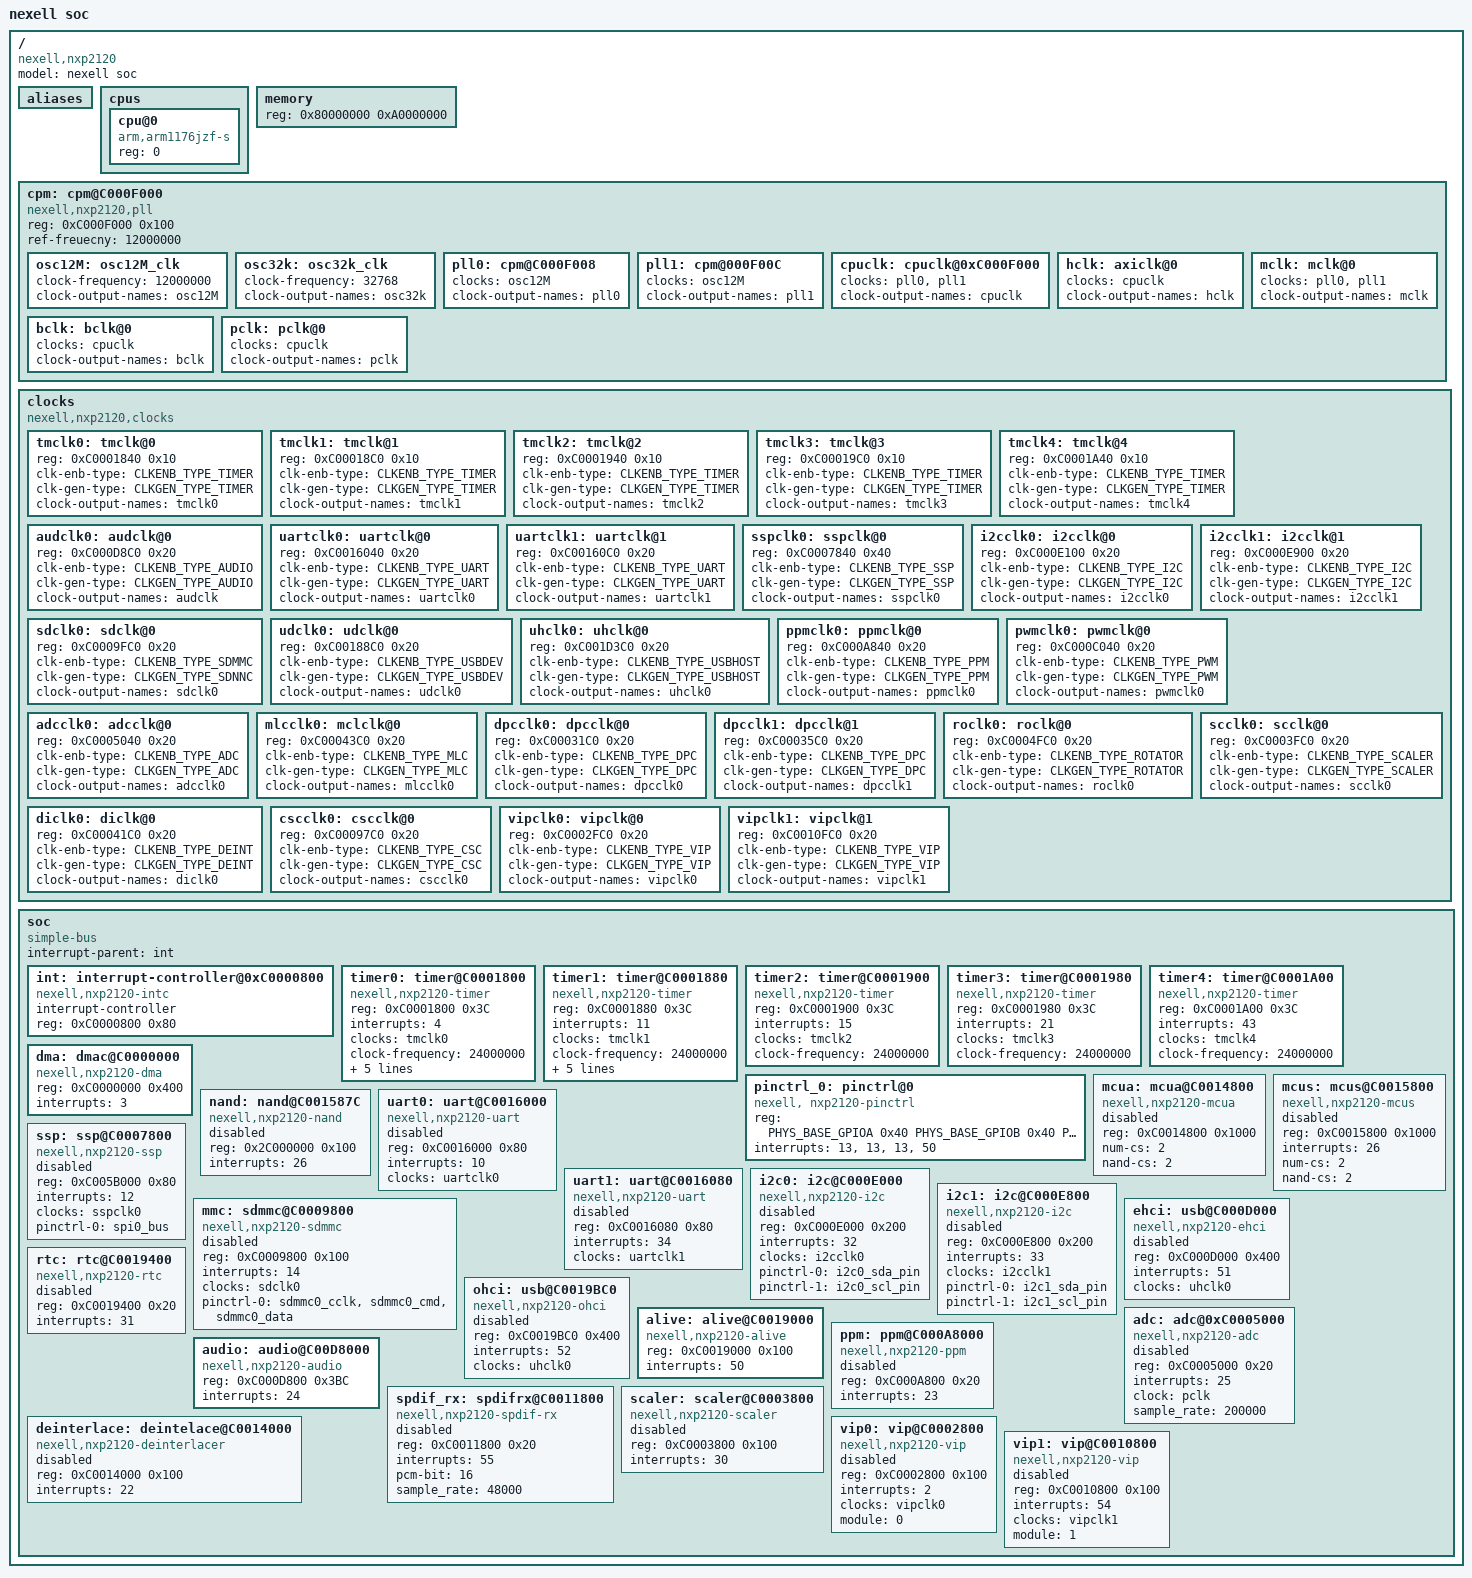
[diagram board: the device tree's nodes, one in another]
/*
 * Copyright (C) 2019 I4VINE
 * Author: Juyoung Ryu <jyryu@i4vine.com>	
 *
 * Copyright (C) 2016 STcube Inc.,
 * All right reserved Seungwoo Kim <ksw@stcube.com>
 *
 * This file is dual-licensed: you can use it either under the terms
 * of the GPL or the X11 license, at your option. Note that this dual
 * licensing only applies to this file, and not this project as a
 * whole.
 *
 *  a) This file is free software; you can redistribute it and/or
 *     modify it under the terms of the GNU General Public License as
 *     published by the Free Software Foundation; either version 2 of the
 *     License, or (at your option) any later version.
 *
 *     This file is distributed in the hope that it will be useful,
 *     but WITHOUT ANY WARRANTY; without even the implied warranty of
 *     MERCHANTABILITY or FITNESS FOR A PARTICULAR PURPOSE.  See the
 *     GNU General Public License for more details.
 *
 * Or, alternatively,
 *
 *  b) Permission is hereby granted, free of charge, to any person
 *     obtaining a copy of this software and associated documentation
 *     files (the "Software"), to deal in the Software without
 *     restriction, including without limitation the rights to use,
 *     copy, modify, merge, publish, distribute, sublicense, and/or
 *     sell copies of the Software, and to permit persons to whom the
 *     Software is furnished to do so, subject to the following
 *     conditions:
 *
 *     The above copyright notice and this permission notice shall be
 *     included in all copies or substantial portions of the Software.
 *
 *     THE SOFTWARE IS PROVIDED "AS IS", WITHOUT WARRANTY OF ANY KIND,
 *     EXPRESS OR IMPLIED, INCLUDING BUT NOT LIMITED TO THE WARRANTIES
 *     OF MERCHANTABILITY, FITNESS FOR A PARTICULAR PURPOSE AND
 *     NONINFRINGEMENT. IN NO EVENT SHALL THE AUTHORS OR COPYRIGHT
 *     HOLDERS BE LIABLE FOR ANY CLAIM, DAMAGES OR OTHER LIABILITY,
 *     WHETHER IN AN ACTION OF CONTRACT, TORT OR OTHERWISE, ARISING
 *     FROM, OUT OF OR IN CONNECTION WITH THE SOFTWARE OR THE USE OR
 *     OTHER DEALINGS IN THE SOFTWARE.
 */
 
/*#include "skeleton.dtsi"
#include <dt-bindings/interrupt-controller/irq.h>*/
#include <dt-bindings/soc/nxp2120-base.h>
#include <dt-bindings/clk/nxp2120-clk.h>
/dts-v1/;


/ {
	model = "nexell soc";
	compatible = "nexell,nxp2120";
	#address-cells = <0x1>;
	#size-cells = <0x1>;
	
	aliases {
		/*pinctrl0 = &pinctrl_0;*/
	};
	cpus {
		#address-cells = <1>;
		#size-cells = <0>;
	/*	enable-method = "nexell,nxp2120-smp";*/
		

		cpu@0 {
			compatible = "arm,arm1176jzf-s","arm,arm1176","arm,armv6";
			device_type = "cpu";
			reg = <0>;
		};
	};
	
	memory {
		reg = <0x80000000 0xA0000000>;
	};

	cpm:cpm@C000F000 {
		compatible = "nexell,nxp2120,pll";
		reg = <0xC000F000 0x100>;
		ref-freuecny = <12000000>;
		status = "okay";

		osc12M: osc12M_clk {
			#clock-cells = <0>;
			clock-frequency = <12000000>;
			clock-output-names = "osc12M";
		};

		osc32k: osc32k_clk {
			#clock-cells = <0>;
			clock-frequency = <32768>;
			clock-output-names = "osc32k";
		};

		pll0: cpm@C000F008 {
			#clock-cells = <0>;
			clocks = <&osc12M>;
			clock-output-names = "pll0";
		};

		pll1: cpm@000F00C {
			#clock-cells = <0>;
			clocks = <&osc12M>;
			clock-output-names = "pll1";
		};

		cpuclk: cpuclk@0xC000F000 {
			#clock-cells = <0>;
			clocks = <&pll0>,<&pll1>;
			clock-output-names = "cpuclk";
		};

		hclk: axiclk@0 {
			#clock-cells = <0>;
			clocks = <&cpuclk>;
			clock-output-names = "hclk";
		};

		mclk: mclk@0 {
			#clock-cells = <0>;
			clocks = <&pll0>,<&pll1>;
			clock-output-names = "mclk";
		};

		bclk: bclk@0 {
			#clock-cells = <0>;
			clocks = <&cpuclk>;
			clock-output-names = "bclk";
		};

		pclk: pclk@0 {
			#clock-cells = <0>;
			clocks = <&cpuclk>;
			clock-output-names = "pclk";
		};

	};

	clocks {
		#address-cells = <1>;
		#size-cells = <1>;
		compatible = "nexell,nxp2120,clocks";
		ranges;

		tmclk0: tmclk@0 {
			reg = <0xC0001840 0x10>;
			clk-enb-type = <CLKENB_TYPE_TIMER>;
			clk-gen-type = <CLKGEN_TYPE_TIMER>;
			clock-output-names = "tmclk0";
		};
		tmclk1: tmclk@1 {
			reg = <0xC00018C0 0x10>;		
			clk-enb-type = <CLKENB_TYPE_TIMER>;
			clk-gen-type = <CLKGEN_TYPE_TIMER>;
			clock-output-names = "tmclk1";
		};
		tmclk2: tmclk@2 {
			reg = <0xC0001940 0x10>;
			clk-enb-type = <CLKENB_TYPE_TIMER>;
			clk-gen-type = <CLKGEN_TYPE_TIMER>;
			clock-output-names = "tmclk2";
		};
		tmclk3: tmclk@3 {
			reg = <0xC00019C0 0x10>;
			clk-enb-type = <CLKENB_TYPE_TIMER>;
			clk-gen-type = <CLKGEN_TYPE_TIMER>;
			clock-output-names = "tmclk3";
		};
		tmclk4: tmclk@4 {
			reg = <0xC0001A40 0x10>;
			clk-enb-type = <CLKENB_TYPE_TIMER>;
			clk-gen-type = <CLKGEN_TYPE_TIMER>;
			clock-output-names = "tmclk4";
		};
		audclk0: audclk@0 {
			reg = <0xC000D8C0 0x20>;
			clk-enb-type = <CLKENB_TYPE_AUDIO>;
			clk-gen-type = <CLKGEN_TYPE_AUDIO>;
			clock-output-names = "audclk";
		};
		uartclk0: uartclk@0 {
			reg = <0xC0016040 0x20>;
			clk-enb-type = <CLKENB_TYPE_UART>;
			clk-gen-type = <CLKGEN_TYPE_UART>;
			clock-output-names = "uartclk0";
		};
		uartclk1: uartclk@1 {
			reg = <0xC00160C0 0x20>;
			clk-enb-type = <CLKENB_TYPE_UART>;
			clk-gen-type = <CLKGEN_TYPE_UART>;
			clock-output-names = "uartclk1";
		};
		sspclk0: sspclk@0 {
			reg = <0xC0007840 0x40>;
			clk-enb-type = <CLKENB_TYPE_SSP>;
			clk-gen-type = <CLKGEN_TYPE_SSP>;
			clock-output-names = "sspclk0";
		};
		i2cclk0: i2cclk@0 {
			reg = <0xC000E100 0x20>;
			clk-enb-type = <CLKENB_TYPE_I2C>;
			clk-gen-type = <CLKGEN_TYPE_I2C>;
			clock-output-names = "i2cclk0";
		};
		i2cclk1: i2cclk@1 {
			reg = <0xC000E900 0x20>;
			clk-enb-type = <CLKENB_TYPE_I2C>;
			clk-gen-type = <CLKGEN_TYPE_I2C>;
			clock-output-names = "i2cclk1";
		};
		sdclk0: sdclk@0 {
			reg = <0xC0009FC0 0x20>;
			clk-enb-type = <CLKENB_TYPE_SDMMC>;
			clk-gen-type = <CLKGEN_TYPE_SDNNC>;			
			clock-output-names = "sdclk0";
		};
		udclk0: udclk@0 {
			reg = <0xC00188C0 0x20>;
			clk-enb-type = <CLKENB_TYPE_USBDEV>;
			clk-gen-type = <CLKGEN_TYPE_USBDEV>;
			clock-output-names="udclk0";
		};
		uhclk0: uhclk@0 {
			reg = <0xC001D3C0 0x20>;
			clk-enb-type = <CLKENB_TYPE_USBHOST>;
			clk-gen-type = <CLKGEN_TYPE_USBHOST>;
			clock-output-names="uhclk0";
		};
		ppmclk0: ppmclk@0 {
			reg = <0xC000A840 0x20>;
			clk-enb-type = <CLKENB_TYPE_PPM>;
			clk-gen-type = <CLKGEN_TYPE_PPM>;
			clock-output-names="ppmclk0";
		};
		pwmclk0: pwmclk@0 {
			reg = <0xC000C040 0x20>;
			clk-enb-type = <CLKENB_TYPE_PWM>;
			clk-gen-type = <CLKGEN_TYPE_PWM>;
			clock-output-names="pwmclk0";
		};
		adcclk0: adcclk@0 {
			reg = <0xC0005040 0x20>;
			clk-enb-type = <CLKENB_TYPE_ADC>;
			clk-gen-type = <CLKGEN_TYPE_ADC>;
			clock-output-names="adcclk0";
		};
		mlcclk0: mclclk@0 {
			reg = <0xC00043C0 0x20>;
			clk-enb-type = <CLKENB_TYPE_MLC>;
			clk-gen-type = <CLKGEN_TYPE_MLC>;
			clock-output-names="mlcclk0";
		};
		dpcclk0: dpcclk@0 {
			reg = <0xC00031C0 0x20>;
			clk-enb-type = <CLKENB_TYPE_DPC>;
			clk-gen-type = <CLKGEN_TYPE_DPC>;
			clock-output-names="dpcclk0";
		};
		dpcclk1: dpcclk@1 {
			reg = <0xC00035C0 0x20>;
			clk-enb-type = <CLKENB_TYPE_DPC>;
			clk-gen-type = <CLKGEN_TYPE_DPC>;
			clock-output-names="dpcclk1";
		};
		roclk0: roclk@0 {
			reg = <0xC0004FC0 0x20>;
			clk-enb-type = <CLKENB_TYPE_ROTATOR>;
			clk-gen-type = <CLKGEN_TYPE_ROTATOR>;
			clock-output-names="roclk0";
		};
		scclk0: scclk@0 {
			reg = <0xC0003FC0 0x20>;
			clk-enb-type = <CLKENB_TYPE_SCALER>;
			clk-gen-type = <CLKGEN_TYPE_SCALER>;
			clock-output-names="scclk0";
		};
		diclk0: diclk@0 {
			reg = <0xC00041C0 0x20>;
			clk-enb-type = <CLKENB_TYPE_DEINT>;
			clk-gen-type = <CLKGEN_TYPE_DEINT>;
			clock-output-names="diclk0";
		};
		cscclk0: cscclk@0 {
			reg = <0xC00097C0 0x20>;
			clk-enb-type = <CLKENB_TYPE_CSC>;
			clk-gen-type = <CLKGEN_TYPE_CSC>;
			clock-output-names="cscclk0";
		};
		vipclk0: vipclk@0 {
			reg = <0xC0002FC0 0x20>;
			clk-enb-type = <CLKENB_TYPE_VIP>;
			clk-gen-type = <CLKGEN_TYPE_VIP>;
			clock-output-names="vipclk0";
		};
		vipclk1: vipclk@1 {
			reg = <0xC0010FC0 0x20>;
			clk-enb-type = <CLKENB_TYPE_VIP>;
			clk-gen-type = <CLKGEN_TYPE_VIP>;
			clock-output-names="vipclk1";
		};
	};
	
	soc {
		compatible = "simple-bus";
		#address-cells = <1>;
		#size-cells = <1>;
		interrupt-parent = <&int>;
		ranges;

		int: interrupt-controller@0xC0000800 {
			compatible = "nexell,nxp2120-intc";
			interrupt-controller;
			reg = <0xC0000800 0x80>;
			#interrupt-cells = <1>;
		};
		
		timer0: timer@C0001800  {
			compatible = "nexell,nxp2120-timer";
			reg = <0xC0001800 0x3C>;		
			interrupts = <4>;		
			clocks =  <&tmclk0>;
			clock-names = "tmclk0";
			clock-frequency = <24000000>;	
			ch = <0>;
			clksrc = <1>; //pll1
			clkdiv = <64>;
			clkfreq = <3000000>;
			period = <0xffffffff>;			
		};
	
		timer1: timer@C0001880  {
			compatible = "nexell,nxp2120-timer";
			reg = <0xC0001880 0x3C>;		
			interrupts = <11>;
			clocks =  <&tmclk1>;
			clock-names = "tmclk1";		
			clock-frequency = <24000000>;
			ch = <1>;
			clksrc = <1>; //pll1
			clkdiv = <192>;
			clkfreq = <1000000>;	
			period = <0xffffffff>;			
		};
		
		timer2: timer@C0001900  {
			compatible = "nexell,nxp2120-timer";
			reg = <0xC0001900 0x3C>;		
			interrupts = <15>;	
			clocks =  <&tmclk2>;
			clock-names = "tmclk2";				
			clock-frequency = <24000000>;
	
		};
		
		timer3: timer@C0001980  {
			compatible = "nexell,nxp2120-timer";
			reg = <0xC0001980 0x3C>;		
			interrupts = <21>;
			clocks =  <&tmclk3>;
			clock-names = "tmclk3";				
			clock-frequency = <24000000>;
		};
		
		timer4: timer@C0001A00  {
			compatible = "nexell,nxp2120-timer";
			reg = <0xC0001A00 0x3C>;		
			interrupts = <43>;	
			clocks =  <&tmclk4>;
			clock-names = "tmclk4";			
			clock-frequency = <24000000>;
		};


		dma: dmac@C0000000 {
			compatible = "nexell,nxp2120-dma";
			reg = <0xC0000000 0x400>;
			interrupts = <3>;
		};
		
		pinctrl_0: pinctrl@0 {
			compatible = "nexell, nxp2120-pinctrl";
			reg = <PHYS_BASE_GPIOA 0x40
				   PHYS_BASE_GPIOB 0x40
				   PHYS_BASE_GPIOC 0x40
				   PHYS_BASE_ALIVE 0xC0>;
			#address-cells = <1>;
			#size-cells = <1>;
			interrupts = <13>,
					 <13>,
					 <13>,   
					 <50>;
		};

		mcua:mcua@C0014800 {
			compatible = "nexell,nxp2120-mcua";
			#address-cells = <1>;
			#size-cells = <0>;
			reg = <0xC0014800 0x1000>;
			num-cs = <2>;
			nand-cs = <2>;
			pinctrl-names = "default";
			status = "disabled";
		};
		
		mcus:mcus@C0015800 {
			compatible = "nexell,nxp2120-mcus";
			#address-cells = <1>;
			#size-cells = <0>;
			reg = <0xC0015800 0x1000>;
			interrupts = <26>;		
			num-cs = <2>;
			nand-cs = <2>;
			pinctrl-names = "default";
			status = "disabled";
		};
		
		nand: nand@C001587C {
			compatible = "nexell,nxp2120-nand";
			#address-cells = <1>;
			#size-cells = <0>;
			reg = <0x2C000000 0x100>;
			interrupts = <26>;
			/* chip-delay = <15>; */
			status = "disabled";
		};
		
		uart0: uart@C0016000 {
			compatible = "nexell,nxp2120-uart";
			reg = <0xC0016000 0x80>;
			interrupts = <10>;
			clock-names = "uartclk";
			clocks = <&uartclk0>;
			pinctrl-names = "default";
		/*	pinctrl-0 = <&serial0_pin>;*/
			status = "disabled";
		};

		uart1: uart@C0016080 {
			compatible = "nexell,nxp2120-uart";
			reg = <0xC0016080 0x80>;
			interrupts = <34>;
			clock-names = "uartclk1";
			clocks = <&uartclk1>;
			pinctrl-names = "default";
		/*	pinctrl-0 = <&serial1_pin>;*/
			status = "disabled";
		};
		
		ssp: ssp@C0007800 {
			compatible = "nexell,nxp2120-ssp";
			reg = <0xC005B000 0x80>;
			interrupts = <12>;
			clock-names = "sspclk0";
			clocks = <&sspclk0>;
			pinctrl-names = "default";
			pinctrl-0 = <&spi0_bus>;
			status = "disabled";
		};

		i2c0: i2c@C000E000 {
			compatible = "nexell,nxp2120-i2c";
			reg = <0xC000E000 0x200>;
			interrupts = <32>;
			clock-names = "i2cclk0";
			clocks = <&i2cclk0>;
			pinctrl-names = "sda0","scl0";
			pinctrl-0 = <&i2c0_sda_pin>;
			pinctrl-1 = <&i2c0_scl_pin>;
			status = "disabled";
		};
		
		i2c1: i2c@C000E800 {
			compatible = "nexell,nxp2120-i2c";
			reg = <0xC000E800 0x200>;
			interrupts = <33>;
			clock-names = "i2cclk1";
			clocks = <&i2cclk1>;
			pinctrl-names = "sda1","scl1";
			pinctrl-0 = <&i2c1_sda_pin>;
			pinctrl-1 = <&i2c1_scl_pin>;
			status = "disabled";
		};

		mmc: sdmmc@C0009800 {
			compatible = "nexell,nxp2120-sdmmc";
			reg = <0xC0009800 0x100>;
			interrupts = <14>;
			clock-names = "sdclk0";
			clocks = <&sdclk0>;
			pinctrl-names = "default";
			pinctrl-0 = <&sdmmc0_cclk &sdmmc0_cmd &sdmmc0_data>;
			status = "disabled";
		};

		ehci: usb@C000D000 {
			compatible = "nexell,nxp2120-ehci", "generic-ehci";
			reg = <0xC000D000 0x400>;
			interrupts = <51>;
			phy-names = "usb";
			clocks = <&uhclk0>;
			clock-names = "uhclk0";
			status = "disabled";
		};

		ohci: usb@C0019BC0 {
			compatible = "nexell,nxp2120-ohci", "generic-ohci";
			reg = <0xC0019BC0 0x400>;
			interrupts = <52>;
			phy-names = "usb";
			clocks = <&uhclk0>;
			clock-names = "uhclk0";
			status = "disabled";
		};
		
		alive: alive@C0019000 {
			compatible = "nexell,nxp2120-alive";
			reg = <0xC0019000 0x100>;
			interrupts = <50>;
		};

		/* watch dog is TIMER4
		wdt: watchdog@C0019000 {
			compatible = "nexell,nxp2120-wdt";
			reg = <0xC0019000 0x20>;      
			clocks = <&pclk>;
			clock-names = "watchdog";
			status = "disabled";
		};
		*/

		rtc: rtc@C0019400 {
			compatible = "nexell,nxp2120-rtc";
			reg = <0xC0019400 0x20>;
			interrupts = <31>;
			status = "disabled";
		};
		
		adc: adc@0xC0005000 {
			compatible = "nexell,nxp2120-adc";
			reg = <0xC0005000 0x20>;
			interrupts = <25>;
			clock = <&pclk>;
			clock-names = "adc";
			sample_rate = <200000>;
			status = "disabled";
			
		};

		ppm: ppm@C000A8000 {
			compatible = "nexell,nxp2120-ppm";
			reg = <0xC000A800 0x20>;
			interrupts = <23>;
			status = "disabled";
		};
		
		audio: audio@C00D8000 {
			compatible = "nexell,nxp2120-audio";
			reg = <0xC000D800 0x3BC>;
			interrupts = <24>;
		};

		spdif_rx: spdifrx@C0011800 {
			compatible = "nexell,nxp2120-spdif-rx";
			reg = <0xC0011800 0x20>;
			interrupts = <55>;
			pcm-bit = <16>;
			sample_rate = <48000>;
			status = "disabled";
		};

		deinterlace: deintelace@C0014000 {
			compatible = "nexell,nxp2120-deinterlacer";
			reg = <0xC0014000 0x100>;
			interrupts = <22>;
			status = "disabled";
		};

		scaler: scaler@C0003800 {
			compatible = "nexell,nxp2120-scaler";
			reg = <0xC0003800 0x100>;
			interrupts = <30>;
			status = "disabled";
		};

		vip0: vip@C0002800 {
			compatible = "nexell,nxp2120-vip";
			reg = <0xC0002800 0x100>;
			interrupts = <2>;
			clock-names = "vipclk0";
			clocks = <&vipclk0>;
			module = <0>;
			status = "disabled";
		};

		vip1: vip@C0010800 {
			compatible = "nexell,nxp2120-vip";
			reg = <0xC0010800 0x100>;
			interrupts = <54>;
			clock-names = "vipclk1";
			clocks = <&vipclk1>;
			module = <1>;
			status = "disabled";
		};
/*		
		gpioa: gpio@C000A000 {
			compatible = "nexell,nxp2120-gpio";
			reg = <0xC000A000 0x40>;
			interrupts = <13>;
		};

		gpiob: gpio@C000A040 {
			compatible = "nexell,nxp2120-gpio";
			reg = <0xC000A040 0x40>;
			interrupts = <13>;
		};

		gpioc: gpio@C000A080 {
			compatible = "nexell,nxp2120-gpio";
			reg = <0xC000A080 0x40>;
			interrupts = <13>;
		};
*/
	};
};
